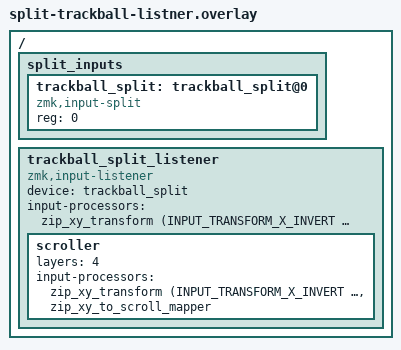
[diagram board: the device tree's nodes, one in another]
#include <input/processors.dtsi>

/ {
    split_inputs {
        #address-cells = <1>;
        #size-cells = <0>;

        trackball_split: trackball_split@0 {
            compatible = "zmk,input-split";
            reg = <0>;
        };
    };

    trackball_split_listener: trackball_split_listener {
        compatible = "zmk,input-listener";
        device = <&trackball_split>;
        status = "okay";

        /* ▼ 常時適用（例：X/Y 反転） */
        input-processors = <
            &zip_xy_transform (INPUT_TRANSFORM_X_INVERT | INPUT_TRANSFORM_Y_INVERT)
        >;

        /* ▼ レイヤー4の間だけ「XY→スクロール」に切り替える */
        scroller {
            layers = <4>;
            input-processors = <
                /* 反転が必要なら、ここにも重ねて書く（上書きルールのため） */
                &zip_xy_transform (INPUT_TRANSFORM_X_INVERT | INPUT_TRANSFORM_Y_INVERT)
                /* XY をホイールに変換 */
                &zip_xy_to_scroll_mapper
            >;
        };
    };
};
